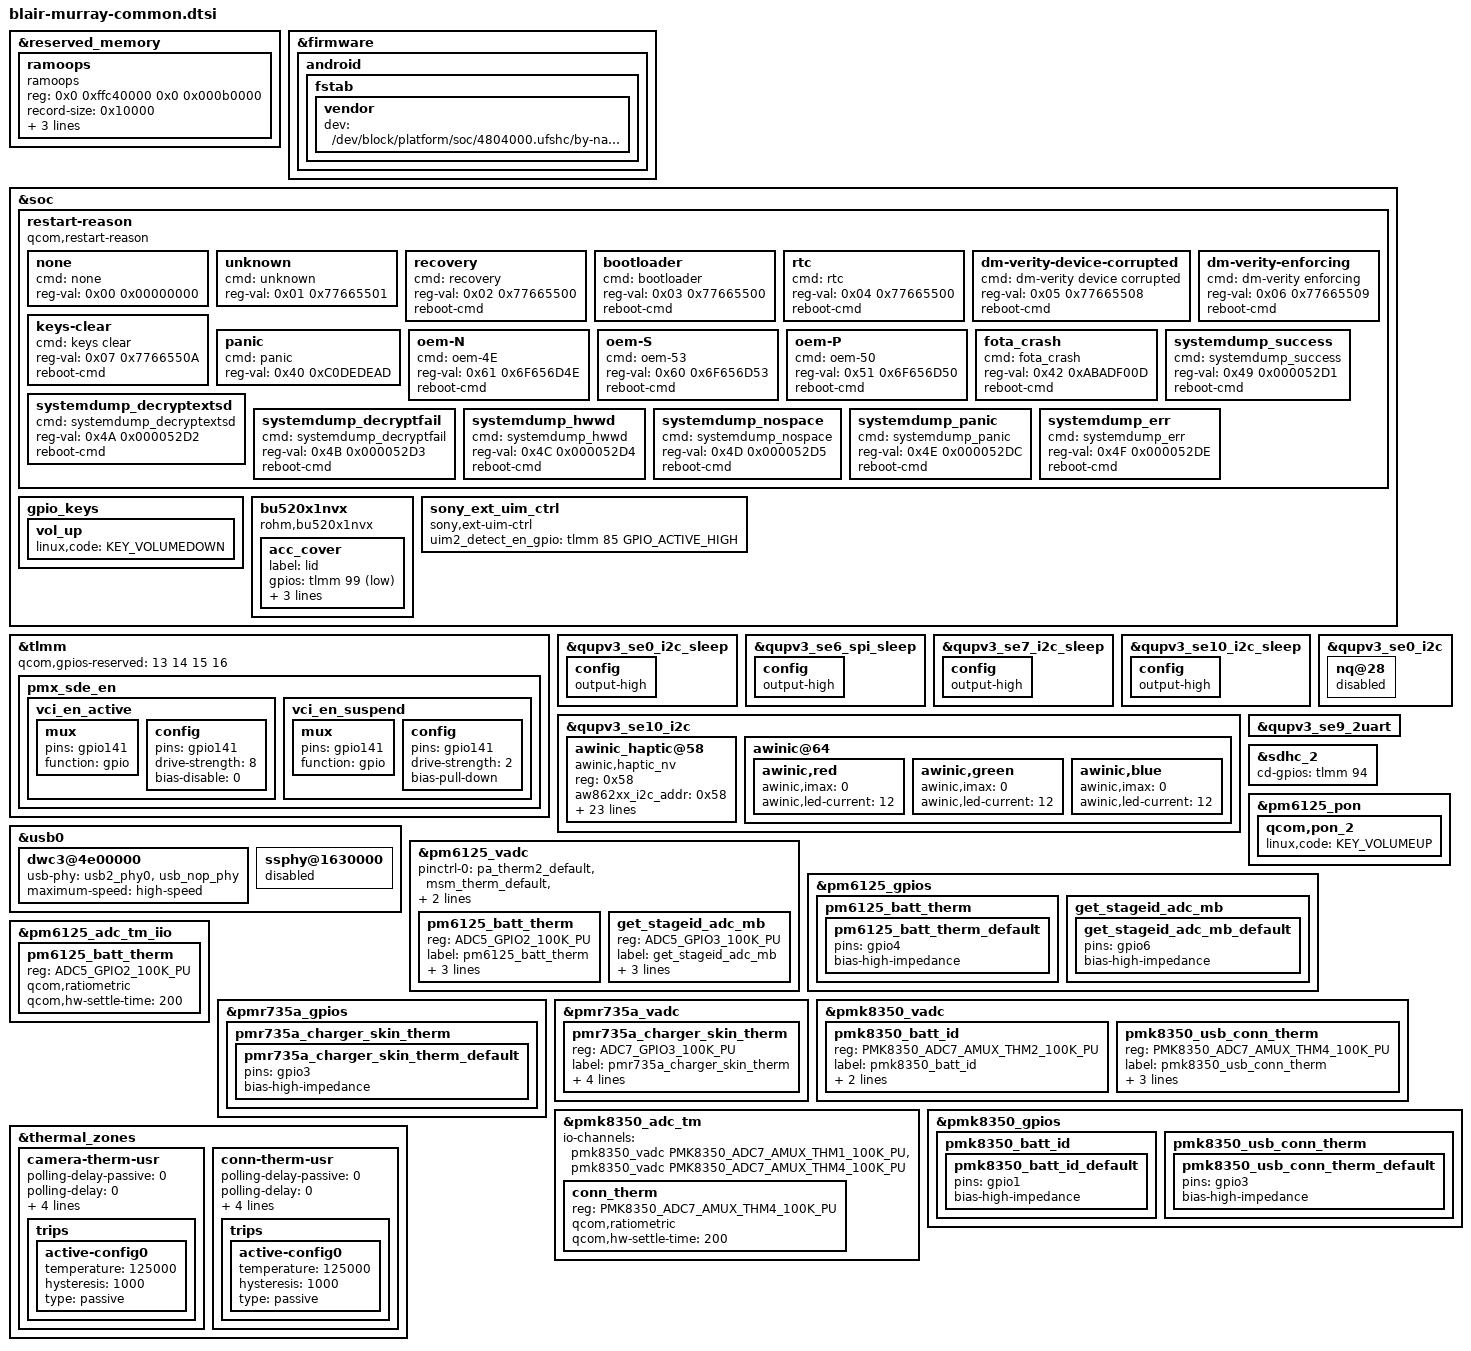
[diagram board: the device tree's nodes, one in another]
&reserved_memory {
	#address-cells = <2>;
	#size-cells = <2>;

	ramoops {
		compatible = "ramoops";
		reg = <0x0 0xffc40000 0x0 0x000b0000>;
		record-size = <0x10000>;
		console-size = <0x40000>;
		ftrace-size = <0x10000>;
		pmsg-size = <0x40000>;
	};
};

&firmware {
	android {
		fstab {
			vendor {
				dev = "/dev/block/platform/soc/4804000.ufshc/by-name/vendor";
			};
		};
	};
};

&soc {
	restart-reason {
		compatible = "qcom,restart-reason";

		none {
			cmd = "none";
			reg-val = <0x00 0x00000000>;
		};

		unknown {
			cmd = "unknown";
			reg-val = <0x01 0x77665501>;
		};

		recovery {
			cmd = "recovery";
			reg-val = <0x02 0x77665500>;
			reboot-cmd;
		};

		bootloader {
			cmd = "bootloader";
			reg-val = <0x03 0x77665500>;
			reboot-cmd;
		};

		rtc {
			cmd = "rtc";
			reg-val = <0x04 0x77665500>;
			reboot-cmd;
		};

		dm-verity-device-corrupted {
			cmd = "dm-verity device corrupted";
			reg-val = <0x05 0x77665508>;
			reboot-cmd;
		};

		dm-verity-enforcing {
			cmd = "dm-verity enforcing";
			reg-val = <0x06 0x77665509>;
			reboot-cmd;
		};

		keys-clear {
			cmd = "keys clear";
			reg-val = <0x07 0x7766550A>;
			reboot-cmd;
		};

		panic {
			cmd = "panic";
			reg-val = <0x40 0xC0DEDEAD>;
		};

		oem-N {
			cmd = "oem-4E";
			reg-val = <0x61 0x6F656D4E>;
			reboot-cmd;
		};

		oem-S {
			cmd = "oem-53";
			reg-val = <0x60 0x6F656D53>;
			reboot-cmd;
		};

		oem-P {
			cmd = "oem-50";
			reg-val = <0x51 0x6F656D50>;
			reboot-cmd;
		};

		fota_crash {
			cmd = "fota_crash";
			reg-val = <0x42 0xABADF00D>;
			reboot-cmd;
		};

		systemdump_success {
			cmd = "systemdump_success";
			reg-val = <0x49 0x000052D1>;
			reboot-cmd;
		};

		systemdump_decryptextsd {
			cmd = "systemdump_decryptextsd";
			reg-val = <0x4A 0x000052D2>;
			reboot-cmd;
		};

		systemdump_decryptfail {
			cmd = "systemdump_decryptfail";
			reg-val = <0x4B 0x000052D3>;
			reboot-cmd;
		};

		systemdump_hwwd {
			cmd = "systemdump_hwwd";
			reg-val = <0x4C 0x000052D4>;
			reboot-cmd;
		};

		systemdump_nospace {
			cmd = "systemdump_nospace";
			reg-val = <0x4D 0x000052D5>;
			reboot-cmd;
		};

		systemdump_panic {
			cmd = "systemdump_panic";
			reg-val = <0x4E 0x000052DC>;
			reboot-cmd;
		};

		systemdump_err {
			cmd = "systemdump_err";
			reg-val = <0x4F 0x000052DE>;
			reboot-cmd;
		};
	};

	gpio_keys {
		vol_up {
			linux,code = <KEY_VOLUMEDOWN>;
		};
	};

	bu520x1nvx {
		compatible = "rohm,bu520x1nvx";

		acc_cover {
			label = "lid";
			gpios = <&tlmm 99 0x1>;
			lid-pin = <1>;
			open-debounce-interval = <120>;
			close-debounce-interval = <300>;
		};
	};

	sony_ext_uim_ctrl {
		compatible = "sony,ext-uim-ctrl";
		uim2_detect_en_gpio = <&tlmm 85 GPIO_ACTIVE_HIGH>;
	};
};

&tlmm {
	qcom,gpios-reserved = <13 14 15 16>;

	pmx_sde_en: pmx_sde_en {
		vci_en_active: vci_en_active {
			mux {
				pins = "gpio141";
				function = "gpio";
			};

			config {
				pins = "gpio141";
				drive-strength = <8>; /* 8 mA */
				bias-disable = <0>; /* no pull */
			};
		};

		vci_en_suspend: vci_en_suspend {
			mux {
				pins = "gpio141";
				function = "gpio";
			};

			config {
				pins = "gpio141";
				drive-strength = <2>; /* 2 mA */
				bias-pull-down; /* PULL DOWN */
			};
		};
	};
};

&qupv3_se0_i2c_sleep {
	config {
		output-high;
	};
};

&qupv3_se6_spi_sleep {
	config {
		output-high;
	};
};

&qupv3_se7_i2c_sleep {
	config {
		output-high;
	};
};

&qupv3_se10_i2c_sleep {
	config {
		output-high;
	};
};

&qupv3_se0_i2c {
	nq@28 {
		status = "disabled";
	};
};

&qupv3_se10_i2c {
	#address-cells = <1>;
	#size-cells = <0>;
	status = "okay";

	awinic_haptic@58 {
		compatible = "awinic,haptic_nv";
		reg = <0x58>;
		aw862xx_i2c_addr = <0x58>;
		reset-gpio = <&tlmm 100 0>;
		irq-gpio = <&tlmm 48 0>;

		aw8622x_vib_lk_f0_cali = <0>;
		aw8622x_vib_mode = <0>; /* mode: RAM mode->0; CONT mode->1 */
		aw8622x_vib_f0_pre = <2350>;
		aw8622x_vib_f0_cali_percen = <7>;
		aw8622x_vib_cont_drv1_lvl = <0x7F>;
		aw8622x_vib_cont_drv2_lvl = <0x36>;
		aw8622x_vib_cont_brk_time = <0x06>;
		aw8622x_vib_cont_tset = <0x06>;
		aw8622x_vib_cont_bemf_set = <0x02>;
		aw8622x_vib_cont_drv_width = <0x6A>;
		aw8622x_vib_cont_wait_num = <0x06>;
		aw8622x_vib_cont_brk_gain = <0x08>;
		aw8622x_vib_cont_drv1_time = <0x04>;
		aw8622x_vib_cont_drv2_time = <0x14>;
		aw8622x_vib_cont_track_margin = <0x12>;
		aw8622x_vib_sine_array = <0x05 0xB2 0xFF 0xEF>; /* SIN_H SIN_L COS_H COS_L*/
		aw8622x_vib_d2s_gain = <0x05>;
		aw8622x_vib_prctmode = <0x2D 0x3E 0x3F>;
		aw8622x_vib_trig_config = <0 0 0 1 0 2 0
					    0 0 0 1 0 2 0
					    0 0 0 1 0 2 0>;
		aw8622x_vib_duration_time = <20 30 60>;
		/*aw8622x_vib_is_enabled_auto_brk;*/
	};

	awinic@64 {
		awinic,red {
			awinic,imax = <0>;
			awinic,led-current = <12>;
		};

		awinic,green {
			awinic,imax = <0>;
			awinic,led-current = <12>;
		};

		awinic,blue {
			awinic,imax = <0>;
			awinic,led-current = <12>;
		};
	};
};

/* Debug UART Instance */
&qupv3_se9_2uart {
	status = "okay";
};

&sdhc_2 {
	cd-gpios = <&tlmm 94 GPIO_ACTIVE_HIGH>;
};

&usb0 {
	dwc3@4e00000 {
		usb-phy = <&usb2_phy0>, <&usb_nop_phy>;
		maximum-speed = "high-speed";
	};

	ssphy@1630000 {
		status = "disabled";
	};
};

&pm6125_pon {
	qcom,pon_2 {
		linux,code = <KEY_VOLUMEUP>;
	};
};

&pm6125_vadc {
	pinctrl-0 = <
			&pa_therm2_default
			&msm_therm_default
			&pm6125_batt_therm_default
			&get_stageid_adc_mb_default>;

	/delete-node/ rfc_cam_therm;
	/delete-node/ rear_cam_flash_therm;

	pm6125_batt_therm {
		reg = <ADC5_GPIO2_100K_PU>;
		label = "pm6125_batt_therm";
		qcom,ratiometric;
		qcom,hw-settle-time = <200>;
		qcom,pre-scaling = <1 1>;
	};

	get_stageid_adc_mb {
		reg = <ADC5_GPIO3_100K_PU>;
		label = "get_stageid_adc_mb";
		qcom,ratiometric;
		qcom,hw-settle-time = <200>;
		qcom,pre-scaling = <1 1>;
	};
};

&pm6125_gpios {
	/delete-node/ rfc_cam_therm;
	/delete-node/ rear_cam_flash_therm;

	pm6125_batt_therm {
		pm6125_batt_therm_default: pm6125_batt_therm_default {
			pins = "gpio4";
			bias-high-impedance;
		};
	};

	get_stageid_adc_mb {
		get_stageid_adc_mb_default: get_stageid_adc_mb_default {
			pins = "gpio6";
			bias-high-impedance;
		};
	};
};

&pm6125_adc_tm_iio {
	/delete-node/ rfc_cam_therm;

	pm6125_batt_therm {
		reg = <ADC5_GPIO2_100K_PU>;
		qcom,ratiometric;
		qcom,hw-settle-time = <200>;
	};
};

&pmr735a_gpios {
	pmr735a_charger_skin_therm {
		pmr735a_charger_skin_therm_default: pmr735a_charger_skin_therm_default {
			pins = "gpio3";
			bias-high-impedance;
		};
	};
};

&pmr735a_vadc {
	status = "okay";

	pmr735a_charger_skin_therm {
		reg = <ADC7_GPIO3_100K_PU>;
		label = "pmr735a_charger_skin_therm";
		qcom,ratiometric;
		qcom,hw-settle-time = <200>;
		qcom,pre-scaling = <1 1>;
		bias-high-impedance;
	};
};

&pmk8350_vadc {
	pmk8350_batt_id {
		reg = <PMK8350_ADC7_AMUX_THM2_100K_PU>;
		label = "pmk8350_batt_id";
		//qcom,ratiometric;
		qcom,hw-settle-time = <200>;
		qcom,pre-scaling = <1 1>;
	};

	pmk8350_usb_conn_therm {
		reg = <PMK8350_ADC7_AMUX_THM4_100K_PU>;
		label = "pmk8350_usb_conn_therm";
		qcom,ratiometric;
		qcom,hw-settle-time = <200>;
		qcom,pre-scaling = <1 1>;
	};
};

&pmk8350_adc_tm {
	io-channels = <&pmk8350_vadc PMK8350_ADC7_AMUX_THM1_100K_PU
		        &pmk8350_vadc PMK8350_ADC7_AMUX_THM4_100K_PU>;

	conn_therm {
		reg = <PMK8350_ADC7_AMUX_THM4_100K_PU>;
		qcom,ratiometric;
		qcom,hw-settle-time = <200>;
	};
};

&pmk8350_gpios {
	pmk8350_batt_id {
		pmk8350_batt_id_default: pmk8350_batt_id_default {
			pins = "gpio1";
			bias-high-impedance;
		};
	};

	pmk8350_usb_conn_therm {
		pmk8350_usb_conn_therm_default: pmk8350_usb_conn_therm_default {
			pins = "gpio3";
			bias-high-impedance;
		};
	};
};

&thermal_zones {
	camera-therm-usr {
		polling-delay-passive = <0>;
		polling-delay = <0>;
		thermal-governor = "user_space";
		thermal-sensors = <&pm6125_adc_tm ADC5_GPIO3_100K_PU>;
		wake-capable-sensor;
		trips {
			active-config0 {
				temperature = <125000>;
				hysteresis = <1000>;
				type = "passive";
			};
		};
	};

	conn-therm-usr {
		polling-delay-passive = <0>;
		polling-delay = <0>;
		thermal-governor = "user_space";
		thermal-sensors = <&pmk8350_adc_tm PMK8350_ADC7_AMUX_THM4_100K_PU>;
		wake-capable-sensor;
		trips {
			active-config0 {
				temperature = <125000>;
				hysteresis = <1000>;
				type = "passive";
			};
		};
	};
};
